AUTOSAR XML (schema 00046)
package /ComponentTypes
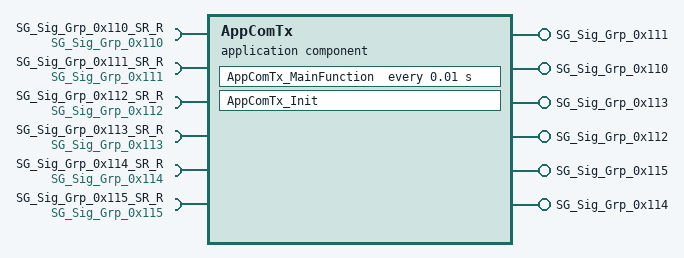
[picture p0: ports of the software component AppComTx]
  application sw component type AppComTx
    6 x provide port:
      SG_Sig_Grp_0x111: nonqueued-sender-com-spec{data-element=SG_Sig_Grp_0x111, init-value=fields=[Button1_State:0, Button2_State:0, Button3_State:0, Button4_State:0]}, provided-interface=SG_Sig_Grp_0x111
      SG_Sig_Grp_0x110: nonqueued-sender-com-spec{data-element=SG_Sig_Grp_0x110, init-value=fields=[Led1_State:0, Led2_State:0, Led3_State:0, Led4_State:0]}, provided-interface=SG_Sig_Grp_0x110
      SG_Sig_Grp_0x113: nonqueued-sender-com-spec{data-element=SG_Sig_Grp_0x113, init-value=fields=System_Run_Time:20}, provided-interface=SG_Sig_Grp_0x113
      SG_Sig_Grp_0x112: nonqueued-sender-com-spec{data-element=SG_Sig_Grp_0x112, uses-end-to-end-protection=true, init-value=fields=[PowerMode:0, SupA_Checksum_0x112:0, SupA_Counter_0x112:0]}, provided-interface=SG_Sig_Grp_0x112
      SG_Sig_Grp_0x115: nonqueued-sender-com-spec{data-element=SG_Sig_Grp_0x115, init-value=fields=[Sig_0x115_Used_1:0, Sig_0x115_Used_2:0, Sig_0x115_Used_3:0, Sig_0x115_Used_4:0, Sig_0x115_Used_5:0]}, provided-interface=SG_Sig_Grp_0x115
      SG_Sig_Grp_0x114: nonqueued-sender-com-spec{data-element=SG_Sig_Grp_0x114, init-value=fields=[Sig_0x114_Used_1:0, Sig_0x114_Used_2:0, Sig_0x114_Used_3:0, Sig_0x114_Used_4:0, Sig_0x114_Used_5:0]}, provided-interface=SG_Sig_Grp_0x114
    6 x require port:
      SG_Sig_Grp_0x110_SR_R: nonqueued-receiver-com-spec{data-element=SG_Sig_Grp_0x110, filter=data-filter-type=ALWAYS, init-value=fields=[Led1_State:0, Led2_State:0, Led3_State:0, Led4_State:0]}, required-interface=SG_Sig_Grp_0x110
      SG_Sig_Grp_0x111_SR_R: nonqueued-receiver-com-spec{data-element=SG_Sig_Grp_0x111, filter=data-filter-type=ALWAYS, init-value=fields=[Button1_State:0, Button2_State:0, Button3_State:0, Button4_State:0]}, required-interface=SG_Sig_Grp_0x111
      SG_Sig_Grp_0x112_SR_R: nonqueued-receiver-com-spec{data-element=SG_Sig_Grp_0x112, filter=data-filter-type=ALWAYS, init-value=fields=[PowerMode:0, SupA_Checksum_0x112:0, SupA_Counter_0x112:0]}, required-interface=SG_Sig_Grp_0x112
      SG_Sig_Grp_0x113_SR_R: nonqueued-receiver-com-spec{data-element=SG_Sig_Grp_0x113, filter=data-filter-type=ALWAYS, init-value=fields=System_Run_Time:20}, required-interface=SG_Sig_Grp_0x113
      SG_Sig_Grp_0x114_SR_R: nonqueued-receiver-com-spec{data-element=SG_Sig_Grp_0x114, filter=data-filter-type=ALWAYS, init-value=fields=[Sig_0x114_Used_1:0, Sig_0x114_Used_2:0, Sig_0x114_Used_3:0, Sig_0x114_Used_4:0, Sig_0x114_Used_5:0]}, required-interface=SG_Sig_Grp_0x114
      SG_Sig_Grp_0x115_SR_R: nonqueued-receiver-com-spec{data-element=SG_Sig_Grp_0x115, filter=data-filter-type=ALWAYS, init-value=fields=[Sig_0x115_Used_1:0, Sig_0x115_Used_2:0, Sig_0x115_Used_3:0, Sig_0x115_Used_4:0, Sig_0x115_Used_5:0]}, required-interface=SG_Sig_Grp_0x115
    behavior AppComTx_InternalBehavior
      init event AppComTx_InitEvent: start-on-event=AppComTx_Init
      timing event TMT_AppComTx_MainFunction: start-on-event=AppComTx_MainFunction, period=0.01
      runnable AppComTx_Init
      runnable AppComTx_MainFunction
        data-receive-point-by-arguments:
          6 x access:
            REC_SG_Sig_Grp_0x{110..115}_SR_R_SG_Sig_Grp_0x{110..115}: accessed-variable=SG_Sig_Grp_0x{110..115}_SR_R.SG_Sig_Grp_0x{110..115}
        data-send-points:
          6 x access:
            SEND_SG_Sig_Grp_0x{110..115}_SG_Sig_Grp_0x{110..115}: accessed-variable=SG_Sig_Grp_0x{110..115}.SG_Sig_Grp_0x{110..115}
  swc implementation AppComTx_Implementation: behavior=AppComTx_InternalBehavior
